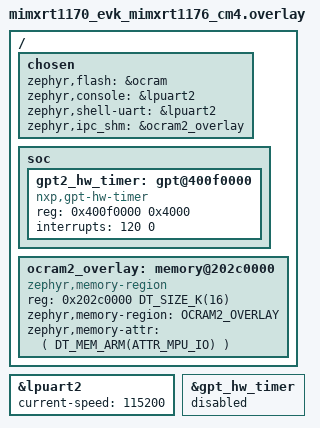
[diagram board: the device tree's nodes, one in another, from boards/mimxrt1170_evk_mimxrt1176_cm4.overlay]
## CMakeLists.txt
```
# Copyright 2023-2026 NXP
#
# SPDX-License-Identifier: BSD-3-Clause

cmake_minimum_required(VERSION 3.20.0)

find_package(Zephyr REQUIRED HINTS $ENV{ZEPHYR_BASE})
project(rpmsglite_remote)
message(STATUS "${BOARD} compiles as Remote Core in this sample")

target_sources(app PRIVATE src/main.c)
target_include_directories(app PRIVATE ${CMAKE_CURRENT_SOURCE_DIR}/..)

# Also include this directory into rpmsg_lite library because of project specific include rpsmg_config.h
target_include_directories(rpmsg_lite PRIVATE ${CMAKE_CURRENT_SOURCE_DIR}/..)

if (CONFIG_BOARD_MIMXRT685_EVK OR CONFIG_BOARD_MIMXRT700_EVK)
    include("${ZEPHYR_BASE}/samples/boards/nxp/adsp/rtxxx/common/remote-dsp-imgs.cmake")
endif()
```

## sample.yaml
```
sample:
  description: RPMSG-Lite Ping Pong sample
  name: rpmsglite pingpong (remote)
tests:
  sample.ipc.rpmsglite_pingpong.remote:
    platform_allow:
      - lpcxpresso54114_m4
      - lpcxpresso55s69_cpu0
      - mimxrt1160_evk_cm7
      - mimxrt1170_evk_cm7
      - mimxrt1170_evkb_cm7
    integration_platforms:
      - mimxrt1170_evk_cm7
    tags: ipm
    harness: remote
```

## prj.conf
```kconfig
# Copyright 2023-2026 NXP
#
# SPDX-License-Identifier: BSD-3-Clause

CONFIG_IPM=y
CONFIG_EVENTS=y
CONFIG_PRINTK=y
CONFIG_RPMSGLITE=y
CONFIG_STDOUT_CONSOLE=n
CONFIG_TIMESLICE_SIZE=1
CONFIG_HEAP_MEM_POOL_SIZE=4096
CONFIG_PLATFORM_SPECIFIC_INIT=n
CONFIG_SEGGER_RTT_BUFFER_SIZE_UP=4096

# Uncomment for Debugging Support
# CONFIG_INIT_STACKS=y
# CONFIG_NO_OPTIMIZATIONS=y
# CONFIG_DEBUG_THREAD_INFO=y
# CONFIG_THREAD_STACK_INFO=y

# CONFIG_HEAP_MEM_POOL_SIZE=65536
# CONFIG_MAIN_STACK_SIZE=65536
# CONFIG_ISR_STACK_SIZE=16384
```

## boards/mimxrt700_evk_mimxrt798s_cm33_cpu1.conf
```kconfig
#
# Copyright 2026 NXP
#
# SPDX-License-Identifier: Apache-2.0
#

CONFIG_BUILD_OUTPUT_INFO_HEADER=y
CONFIG_BUILD_OUTPUT_HEX=y
CONFIG_SECOND_CORE_MCUX=y
CONFIG_RPMSG_LITE_ENABLE_CACHE=y
```

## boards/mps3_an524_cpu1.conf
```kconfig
# Copyright 2026 Arm Limited and/or its affiliates <open-source-office@arm.com>
#
# SPDX-License-Identifier: BSD-3-Clause

CONFIG_IPM=y
CONFIG_EVENTS=y
CONFIG_PRINTK=y
CONFIG_RPMSGLITE=y
CONFIG_TIMESLICE_SIZE=1
CONFIG_HEAP_MEM_POOL_SIZE=4096
```

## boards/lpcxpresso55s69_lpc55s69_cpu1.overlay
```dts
/*
 * Copyright (c) 2019 Linaro Limited
 * Copyright 2023 NXP
 *
 * SPDX-License-Identifier: BSD-3-Clause
 */

/ {
	chosen {
		/*
		 * shared memory reserved for the inter-processor communication
		 */

		zephyr,ipc_shm = &sram4duplicate;
		zephyr,ipc = &mailbox0;
	};

	/* This is a duplication of sram4, workaround */
	sram4duplicate: memory@20040000 {
		compatible = "mmio-sram";
		reg = <0x20040000 DT_SIZE_K(16)>;
	};
};
```

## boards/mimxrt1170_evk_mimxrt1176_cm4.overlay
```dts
/*
 * Copyright 2023 NXP
 *
 * SPDX-License-Identifier: BSD-3-Clause
 */

#include <zephyr/dt-bindings/memory-attr/memory-attr-arm.h>

/ {
	/* Switch to lpuart2, since primary core uses lpuart1 */
	chosen {
		zephyr,flash = &ocram;
		zephyr,console = &lpuart2;
		zephyr,shell-uart = &lpuart2;
		zephyr,ipc_shm = &ocram2_overlay;
	};

	soc {
		/delete-node/ gpt@400f0000;

		/* Replace GPT2 with another GPT kernel timer */
		gpt2_hw_timer:gpt@400f0000 {
			compatible = "nxp,gpt-hw-timer";
			reg = <0x400f0000 0x4000>;
			interrupts = <120 0>;
			status = "okay";
		};
	};

	/* OpenAMP fails with full 512K OCRAM2 memory region as shared memory.
	 * Define a subset of the OCRAM2 region for demo to use
	 * Note that shared memory must have specific MPU attributes set
	 */
	ocram2_overlay: memory@202c0000 {
		compatible = "zephyr,memory-region", "mmio-sram";
		reg = <0x202c0000 DT_SIZE_K(16)>;
		zephyr,memory-region="OCRAM2_OVERLAY";
		zephyr,memory-attr = <( DT_MEM_ARM(ATTR_MPU_IO) )>;
	};
};

/* Enable secondary LPUART */
&lpuart2 {
	status = "okay";
	current-speed = <115200>;
};

/* Disable primary GPT timer */
&gpt_hw_timer {
	status = "disabled";
};
```

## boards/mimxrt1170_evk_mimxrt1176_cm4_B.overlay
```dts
/*
 * Copyright 2023 NXP
 *
 * SPDX-License-Identifier: BSD-3-Clause
 */

#include <zephyr/dt-bindings/memory-attr/memory-attr-arm.h>

/ {
	/* Switch to lpuart2, since primary core uses lpuart1 */
	chosen {
		zephyr,flash = &ocram;
		zephyr,console = &lpuart1;
		zephyr,shell-uart = &lpuart1;
		zephyr,ipc_shm = &ocram2_overlay;
	};

	soc {
		/delete-node/ gpt@400f0000;

		/* Replace GPT2 with another GPT kernel timer */
		gpt2_hw_timer:gpt@400f0000 {
			compatible = "nxp,gpt-hw-timer";
			reg = <0x400f0000 0x4000>;
			interrupts = <120 0>;
			status = "okay";
		};
	};

	/* OpenAMP fails with full 512K OCRAM2 memory region as shared memory.
	 * Define a subset of the OCRAM2 region for demo to use
	 * Note that shared memory must have specific MPU attributes set
	 */
	ocram2_overlay: memory@202c0000 {
		compatible = "zephyr,memory-region", "mmio-sram";
		reg = <0x202c0000 DT_SIZE_K(16)>;
		zephyr,memory-region="OCRAM2_OVERLAY";
		zephyr,memory-attr = <( DT_MEM_ARM(ATTR_MPU_IO) )>;
	};
};

/* Enable secondary LPUART */
&lpuart2 {
	status = "okay";
	current-speed = <115200>;
};

/* Disable primary GPT timer */
&gpt_hw_timer {
	status = "disabled";
};
```

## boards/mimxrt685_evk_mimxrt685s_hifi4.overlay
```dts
/*
 * Copyright 2026 NXP
 *
 * SPDX-License-Identifier: Apache-2.0
 */

#include <zephyr/dt-bindings/ipc_service/static_vrings.h>
#include <zephyr/dt-bindings/memory-attr/memory-attr-arm.h>

/ {
	chosen {
		/*
		 * shared memory reserved for the inter-processor communication
		 */

		zephyr,ipc_shm = &sram_sh_mem;
		zephyr,ipc = &mailbox_b;
	};

	/* Define memory regions for IPC */
	sram_sh_mem: memory@20070000 {
		compatible = "zephyr,memory-region", "mmio-sram";
		reg = <0x20070000 DT_SIZE_K(32)>;
		zephyr,memory-region = "SRAM_SH_MEM";
		zephyr,memory-attr = <DT_MEM_ARM(ATTR_MPU_IO)>;
	};

	mailbox_b: ipm-mbox {
		compatible = "zephyr,mbox-ipm";
		mboxes = <&mbox 0>, <&mbox 1>;
		mbox-names = "tx", "rx";
	};
};
```

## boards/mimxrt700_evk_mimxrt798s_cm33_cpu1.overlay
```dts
/*
 * Copyright 2026 NXP
 *
 * SPDX-License-Identifier: Apache-2.0
 */

#include <zephyr/dt-bindings/ipc_service/static_vrings.h>
#include <zephyr/dt-bindings/memory-attr/memory-attr-arm.h>

/ {
	chosen {
		zephyr,ipc_shm = &sram_shared_mem_m33;
		zephyr,ipc = &mailbox_b;
	};

	mailbox_b: ipm-mbox {
		compatible = "zephyr,mbox-ipm";
		mboxes = <&mbox1_b 0>, <&mbox1_b 1>;
		mbox-names = "tx", "rx";
	};

	/* Define memory regions */
	sram_shared_mem_m33: memory@20580000 {
		compatible = "zephyr,memory-region", "mmio-sram";
		reg = <0x20580000 DT_SIZE_K(16)>;
		zephyr,memory-region = "SRAM_SHARED_M33";
		zephyr,memory-attr = <DT_MEM_ARM(ATTR_MPU_IO)>;
	};
};
```

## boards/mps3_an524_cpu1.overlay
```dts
/*
 * Copyright 2026 Arm Limited and/or its affiliates <open-source-office@arm.com>
 *
 * SPDX-License-Identifier: BSD-3-Clause
 */

/ {
	chosen {
		/*
		 * shared memory reserved for the inter-processor communication
		 */
		zephyr,ipc_shm = &sramx;
		zephyr,ipc = &mhu0;
	};

	/* top 32 KB of the BRAM, non-secure alias.
	 * The addresses must match the cpu0 overlay exactly. */
	sramx: memory@28078000 {
		compatible = "mmio-sram";
		reg = <0x28078000 0x8000>;
	};
};
```

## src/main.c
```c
/*
 * Copyright 2023-2026 NXP
 *
 * SPDX-License-Identifier: BSD-3-Clause
 */

#include <zephyr/drivers/ipm.h>
#include <zephyr/sys/printk.h>
#include <zephyr/device.h>
#include <stdio.h>
#include <stdlib.h>
#include <string.h>
#include <zephyr/init.h>

#include "common.h"
#include "rpmsg_lite.h"

#define LOCAL_EPT_ADDR                (30U)
#define APP_RPMSG_READY_EVENT_DATA    (1U)
#define APP_RPMSG_EP_READY_EVENT_DATA (2U)

#define SHM_MEM_ADDR DT_REG_ADDR(DT_CHOSEN(zephyr_ipc_shm))
#define SHM_MEM_SIZE DT_REG_SIZE(DT_CHOSEN(zephyr_ipc_shm))

#define APP_THREAD_STACK_SIZE (4096)
K_THREAD_STACK_DEFINE(thread_stack, APP_THREAD_STACK_SIZE);
static struct k_thread thread_data;

struct rpmsg_lite_instance *gp_rpmsg_dev_inst;
struct rpmsg_lite_endpoint *gp_rpmsg_ept;
struct rpmsg_lite_instance g_rpmsg_ctxt;
struct rpmsg_lite_ept_static_context g_ept_context;
volatile int32_t g_has_received;

uint32_t *shared_memory = (uint32_t *)SHM_MEM_ADDR;

typedef struct the_message
{
    uint32_t DATA;
} THE_MESSAGE, *THE_MESSAGE_PTR;

static THE_MESSAGE volatile g_msg = {0};
static uint32_t g_remote_addr     = 0;

/* Internal functions */
static int32_t rpmsg_ept_read_cb(void *payload, uint32_t payload_len, uint32_t src, void *priv)
{
    int32_t *has_received = priv;

    if (payload_len <= sizeof(THE_MESSAGE))
    {
        (void)memcpy((void *)&g_msg, payload, payload_len);
        g_remote_addr = src;
        *has_received = 1;
    }
    return RL_RELEASE;
}

static void application_thread(void *arg1, void *arg2, void *arg3)
{
    ARG_UNUSED(arg1);
    ARG_UNUSED(arg2);
    ARG_UNUSED(arg3);

    gp_rpmsg_dev_inst = rpmsg_lite_remote_init(shared_memory, RPMSG_LITE_LINK_ID, RL_NO_FLAGS, &g_rpmsg_ctxt);

    rpmsg_lite_wait_for_link_up(gp_rpmsg_dev_inst, 600000);

    gp_rpmsg_ept = rpmsg_lite_create_ept(gp_rpmsg_dev_inst, LOCAL_EPT_ADDR, rpmsg_ept_read_cb, (void *)&g_has_received,
                                         &g_ept_context);

    while (g_msg.DATA <= 100U)
    {
        if (1 == g_has_received)
        {
            g_has_received = 0;
            g_msg.DATA++;
            (void)rpmsg_lite_send(gp_rpmsg_dev_inst, gp_rpmsg_ept, g_remote_addr, (char *)&g_msg, sizeof(THE_MESSAGE),
                                  RL_DONT_BLOCK);
        }
    }

    (void)rpmsg_lite_destroy_ept(gp_rpmsg_dev_inst, gp_rpmsg_ept);
    gp_rpmsg_ept = ((void *)0);
    (void)rpmsg_lite_deinit(gp_rpmsg_dev_inst);
    g_msg.DATA = 0U;
}

int main(void)
{
    printk("Starting application thread on Remote Core!\n");
    k_thread_create(&thread_data, thread_stack, APP_THREAD_STACK_SIZE, application_thread, NULL, NULL, NULL,
                    K_PRIO_COOP(7), 0, K_NO_WAIT);

    return 0;
}
```
